# ATSAMA5D31 register map
Vendor: Atmel; Series: SAMA5D3; File version: 20130221
Registers are 32-bit, read-write, reset 0x0 unless marked. A register's access mark holds for its fields unless they carry their own. Offsets are from the block's base; [hi:lo] are bit positions; {n}, {i} and the like mark numbered series; 'fields as' and 'values as' point back to an identical list.

## SFR — Special Function Registers
Base 0xF0038000; register names take the prefix SFR_
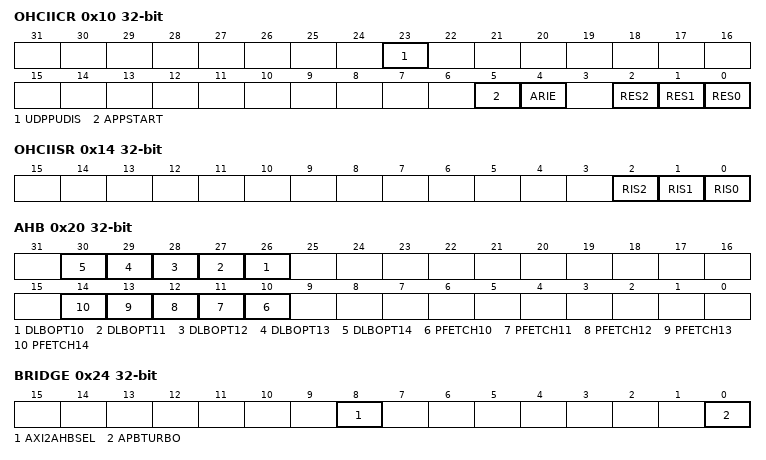
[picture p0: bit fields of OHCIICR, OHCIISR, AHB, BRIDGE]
0x10 OHCIICR — OHCI Interrupt Configuration Register
  [23] UDPPUDIS — OHCI USB DEVICE PULL-UP DISABLE
  [5] APPSTART — Reserved
  [4] ARIE — OHCI Asynchronous Resume Interrupt Enable
  [2] RES2 — USB PORTx RESET
  [1] RES1 — USB PORTx RESET
  [0] RES0 — USB PORTx RESET
0x14 OHCIISR ro reset not defined — OHCI Interrupt Status Register
  [2] RIS2 — OHCI Resume Interrupt Status Port 2
  [1] RIS1 — OHCI Resume Interrupt Status Port 1
  [0] RIS0 — OHCI Resume Interrupt Status Port 0
0x20 AHB — AHB Configuration Register
  [n+16] DLBOPT{n} (n=10..14) — AHB MASTERx {n} Converter Define Length Burst Optimization
  [n] PFETCH{n} (n=10..14) — AHB MASTERx {n} Converter Prefetch
    0=INCR4 (INCR undefined burst converted to burst of 4 beats.); 1=INCR8 (INCR undefined burst converted to burst of 8 beats.)
0x24 BRIDGE — Bridge Configuration Register
  [8] AXI2AHBSEL — AXI to AHB bridge for DDR controller selection
    0=SINGLE (use single port bridge.); 1=DUAL (use dual port bridge.)
  [0] APBTURBO — AHB to APB Bridge mode
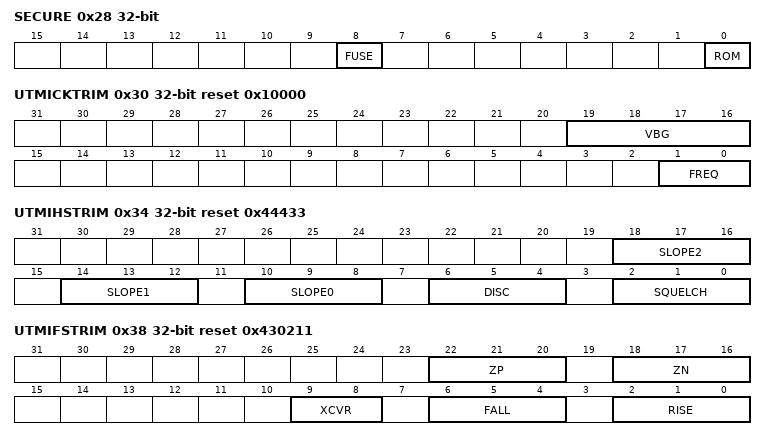
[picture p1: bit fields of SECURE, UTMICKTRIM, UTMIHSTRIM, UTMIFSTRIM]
0x28 SECURE — Security Configuration Register
  [8] FUSE — Disable Access to Fuse Controller
  [0] ROM — Disable Access to ROM Code
0x30 UTMICKTRIM reset 0x10000 — UTMI Clock Trimming Register
  [19:16] VBG — UTMI Band Gap Voltage Trimming
  [1:0] FREQ — UTMI Reference Clock Frequency
    0=12 MHz reference clock; 1=16 MHz reference clock; 2=24 MHz reference clock; 3=48 MHz reference clock
0x34 UTMIHSTRIM reset 0x44433 — UTMI High Speed Trimming Register
  [18:16] SLOPE2 — UTMI HS PORTx Transceiver Slope Trimming
  [14:12] SLOPE1 — UTMI HS PORTx Transceiver Slope Trimming
  [10:8] SLOPE0 — UTMI HS PORTx Transceiver Slope Trimming
  [6:4] DISC — UTMI Disconnect Voltage Trimming
  [2:0] SQUELCH — UTMI HS SQUELCH Voltage Trimming
0x38 UTMIFSTRIM reset 0x430211 — UTMI Full Speed Trimming Register
  [22:20] ZP — FS Transceiver PMOS impedance trimming
  [18:16] ZN — FS Transceiver NMOS impedance trimming
  [9:8] XCVR — FS Transceiver crossover voltage trimming
  [6:4] FALL — FS Transceiver output falling slope trimming
  [2:0] RISE — FS Transceiver output rising slope trimming
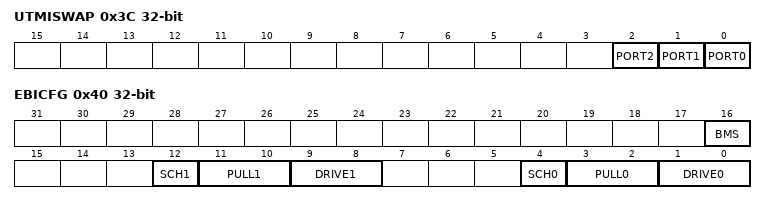
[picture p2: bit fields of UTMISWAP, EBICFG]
0x3C UTMISWAP — UTMI DP/DM Pin Swapping Register
  [all] fields
    0=NORMAL (DP/DM normal pinout.); 1=SWAPPED (DP/DM swapped pinout.)
  [2] PORT2 — PORT 2 DP/DM Pin Swapping
  [1] PORT1 — PORT 1 DP/DM Pin Swapping
  [0] PORT0 — PORT 0 DP/DM Pin Swapping
0x40 EBICFG reset not defined — EBI Configuration Register
  [16] BMS — BMS Sampled Value (Read Only)
    0=ROM (Boot on ROM.); 1=EBI (Boot on EBI.)
  [12] SCH1 — EBI Pins Schmitt Trigger
  [11:10] PULL1 — EBI Pins Pull Value
    0=UP (Pull-up); 1=NONE (No Pull); 3=DOWN (Pull-down)
  [9:8] DRIVE1 — EBI Pins Drive Level
    0=LOW (Low drive level); 2=MEDIUM (Medium drive level); 3=HIGH (High drive level)
  [4] SCH0 — EBI Pins Schmitt Trigger
  [3:2] PULL0 — EBI Pins Pull Value
    0=UP (Pull-up); 1=NONE (No Pull); 3=DOWN (Pull-down)
  [1:0] DRIVE0 — EBI Pins Drive Level
    values as DRIVE1

## TRNG — True Random Number Generator
Base 0xF8040000; register names take the prefix TRNG_
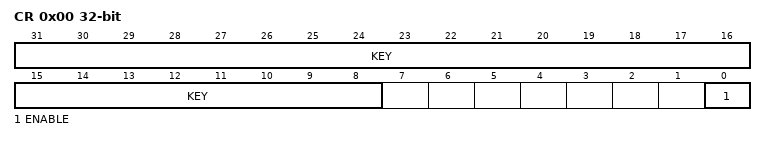
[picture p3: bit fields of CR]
0x00 CR wo reset not defined — Control Register
  [31:8] KEY — Security Key
  [0] ENABLE — Enables the TRNG to provide random values
0x10 IER wo reset not defined — Interrupt Enable Register
  [0] DATRDY — Data Ready Interrupt Enable
0x14 IDR wo reset not defined — Interrupt Disable Register
  [0] DATRDY — Data Ready Interrupt Disable
0x18 IMR ro — Interrupt Mask Register
  [0] DATRDY — Data Ready Interrupt Mask
0x1C ISR ro — Interrupt Status Register
  [0] DATRDY — Data Ready
0x50 ODATA ro — Output Data Register
  [31:0] ODATA — Output Data
